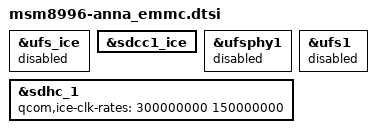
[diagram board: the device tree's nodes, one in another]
/* Copyright (c) 2015, The Linux Foundation. All rights reserved.
 *
 * This program is free software; you can redistribute it and/or modify
 * it under the terms of the GNU General Public License version 2 and
 * only version 2 as published by the Free Software Foundation.
 *
 * This program is distributed in the hope that it will be useful,
 * but WITHOUT ANY WARRANTY; without even the implied warranty of
 * MERCHANTABILITY or FITNESS FOR A PARTICULAR PURPOSE.  See the
 * GNU General Public License for more details.
 */

/* Current storage type is EMMC */

&ufs_ice {
	status = "disabled";
};

&sdcc1_ice {
        status = "ok";
};

&ufsphy1 {
	status = "disabled";
};

&ufs1 {
	status = "disabled";
};

&sdhc_1 {
	qcom,ice-clk-rates = <300000000 150000000>;
};


